# PIC32MK0512GPG048 register map
Vendor: Microchip
Registers are 32-bit, read-write, reset 0x0 unless marked. A register's access mark holds for its fields unless they carry their own. Addresses are absolute, and some are shared; only a register's first bit layout is shown; [hi:lo] are bit positions; {n}, {i} and the like mark numbered series.

## CLC4
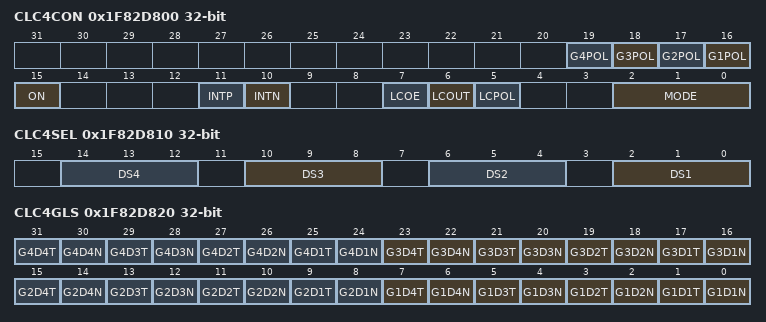
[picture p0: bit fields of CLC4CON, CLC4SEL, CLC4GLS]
0x1F82D800 CLC4CON
  [n+15] G{n}POL (n=1..4), [15] ON, [11] INTP, [10] INTN, [7] LCOE, [6] LCOUT, [5] LCPOL, [2:0] MODE
0x1F82D810 CLC4SEL
  [4n-2:4n-4] DS{n} (n=1..4)
0x1F82D820 CLC4GLS
  [8n-1] G{n}D4T (n=1..4), [8n-2] G{n}D4N (n=1..4), [8n-3] G{n}D3T (n=1..4), [8n-4] G{n}D3N (n=1..4), [8n-5] G{n}D2T (n=1..4), [8n-6] G{n}D2N (n=1..4), [8n-7] G{n}D1T (n=1..4), [8n-8] G{n}D1N (n=1..4)

## gpio_ports_upb
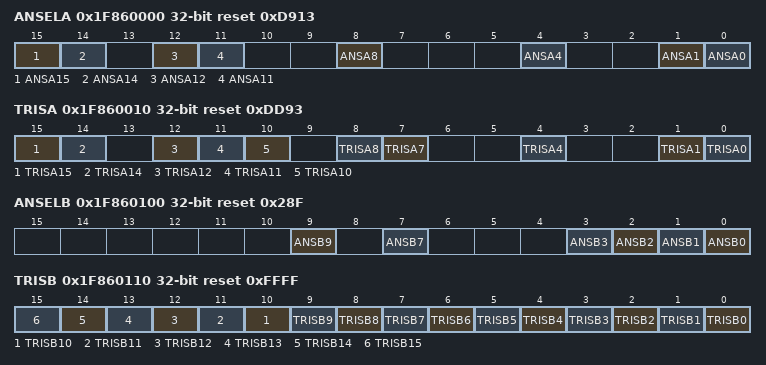
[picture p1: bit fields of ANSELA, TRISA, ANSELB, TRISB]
0x1F860000 ANSELA reset 0xD913
  [15] ANSA15, [14] ANSA14, [12] ANSA12, [11] ANSA11, [8] ANSA8, [4] ANSA4, [1] ANSA1, [0] ANSA0
0x1F860010 TRISA reset 0xDD93
  [15] TRISA15, [14] TRISA14, [12] TRISA12, [11] TRISA11, [10] TRISA10, [8] TRISA8, [7] TRISA7, [4] TRISA4, [1] TRISA1, [0] TRISA0
0x1F860100 ANSELB reset 0x28F
  [9] ANSB9, [7] ANSB7, [n] ANSB{n} (n=0..3)
0x1F860110 TRISB reset 0xFFFF
  [n] TRISB{n} (n=0..15)
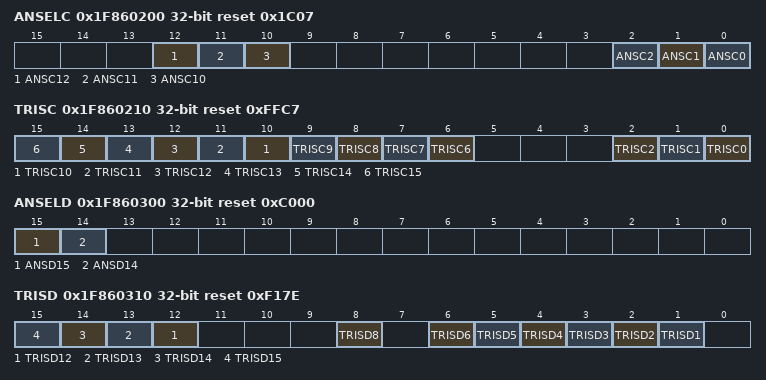
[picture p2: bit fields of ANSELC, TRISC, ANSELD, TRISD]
0x1F860200 ANSELC reset 0x1C07
  [12] ANSC12, [11] ANSC11, [10] ANSC10, [2] ANSC2, [1] ANSC1, [0] ANSC0
0x1F860210 TRISC reset 0xFFC7
  [n] TRISC{n} (n=6..15), [2] TRISC2, [1] TRISC1, [0] TRISC0
0x1F860300 ANSELD reset 0xC000
  [15] ANSD15, [14] ANSD14
0x1F860310 TRISD reset 0xF17E
  [n] TRISD{n} (n=12..15), [8] TRISD8, [n] TRISD{n} (n=1..6)

## PORTA
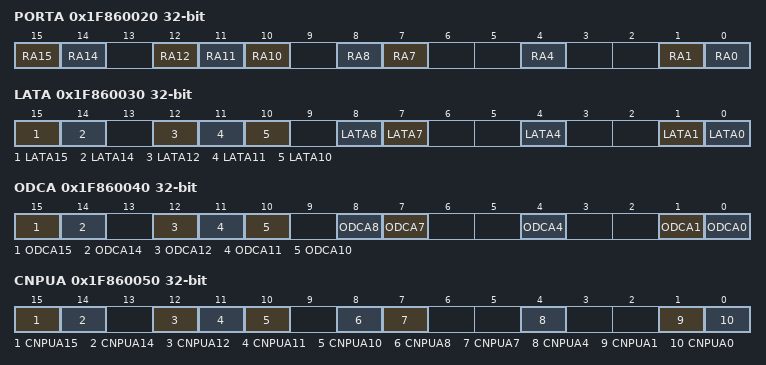
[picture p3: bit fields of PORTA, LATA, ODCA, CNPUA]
0x1F860020 PORTA reset not defined — (power-on value ----------------xx-xxx-xx--x--xx)
  [15] RA15, [14] RA14, [12] RA12, [11] RA11, [10] RA10, [8] RA8, [7] RA7, [4] RA4, [1] RA1, [0] RA0
0x1F860030 LATA reset not defined — (power-on value ----------------xx-xxx-xx--x--xx)
  [15] LATA15, [14] LATA14, [12] LATA12, [11] LATA11, [10] LATA10, [8] LATA8, [7] LATA7, [4] LATA4, [1] LATA1, [0] LATA0
0x1F860040 ODCA
  [15] ODCA15, [14] ODCA14, [12] ODCA12, [11] ODCA11, [10] ODCA10, [8] ODCA8, [7] ODCA7, [4] ODCA4, [1] ODCA1, [0] ODCA0
0x1F860050 CNPUA
  [15] CNPUA15, [14] CNPUA14, [12] CNPUA12, [11] CNPUA11, [10] CNPUA10, [8] CNPUA8, [7] CNPUA7, [4] CNPUA4, [1] CNPUA1, [0] CNPUA0
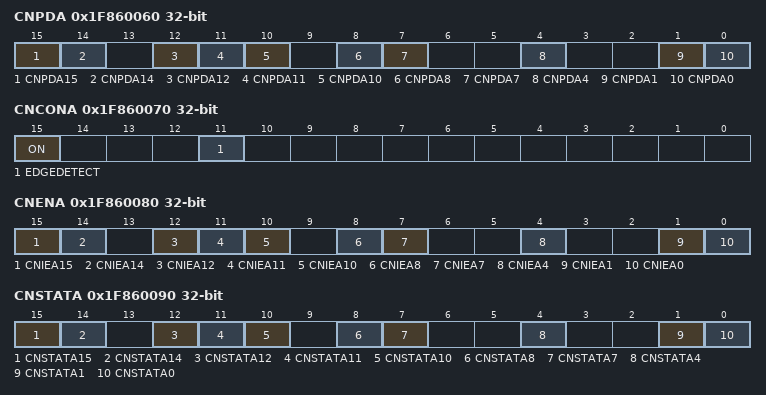
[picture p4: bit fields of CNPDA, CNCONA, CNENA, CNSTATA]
0x1F860060 CNPDA
  [15] CNPDA15, [14] CNPDA14, [12] CNPDA12, [11] CNPDA11, [10] CNPDA10, [8] CNPDA8, [7] CNPDA7, [4] CNPDA4, [1] CNPDA1, [0] CNPDA0
0x1F860070 CNCONA
  [15] ON, [11] EDGEDETECT
0x1F860080 CNENA
  [15] CNIEA15, [14] CNIEA14, [12] CNIEA12, [11] CNIEA11, [10] CNIEA10, [8] CNIEA8, [7] CNIEA7, [4] CNIEA4, [1] CNIEA1, [0] CNIEA0
0x1F860090 CNSTATA
  [15] CNSTATA15, [14] CNSTATA14, [12] CNSTATA12, [11] CNSTATA11, [10] CNSTATA10, [8] CNSTATA8, [7] CNSTATA7, [4] CNSTATA4, [1] CNSTATA1, [0] CNSTATA0
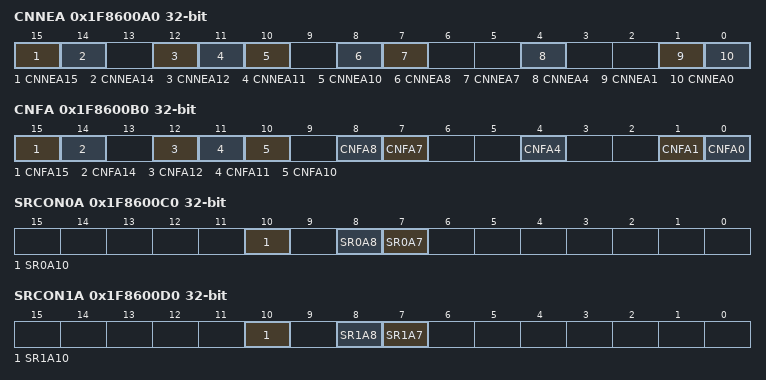
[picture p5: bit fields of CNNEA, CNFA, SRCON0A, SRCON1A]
0x1F8600A0 CNNEA
  [15] CNNEA15, [14] CNNEA14, [12] CNNEA12, [11] CNNEA11, [10] CNNEA10, [8] CNNEA8, [7] CNNEA7, [4] CNNEA4, [1] CNNEA1, [0] CNNEA0
0x1F8600B0 CNFA
  [15] CNFA15, [14] CNFA14, [12] CNFA12, [11] CNFA11, [10] CNFA10, [8] CNFA8, [7] CNFA7, [4] CNFA4, [1] CNFA1, [0] CNFA0
0x1F8600C0 SRCON0A
  [10] SR0A10, [8] SR0A8, [7] SR0A7
0x1F8600D0 SRCON1A
  [10] SR1A10, [8] SR1A8, [7] SR1A7

## PORTB
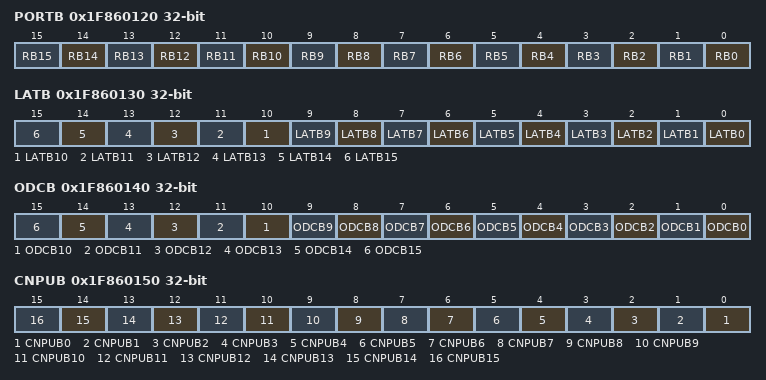
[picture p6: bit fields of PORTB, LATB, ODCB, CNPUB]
0x1F860120 PORTB reset not defined — (power-on value ----------------xxxxxxxxxxxxxxxx)
  [n] RB{n} (n=0..15)
0x1F860130 LATB reset not defined — (power-on value ----------------xxxxxxxxxxxxxxxx)
  [n] LATB{n} (n=0..15)
0x1F860140 ODCB
  [n] ODCB{n} (n=0..15)
0x1F860150 CNPUB
  [n] CNPUB{n} (n=0..15)
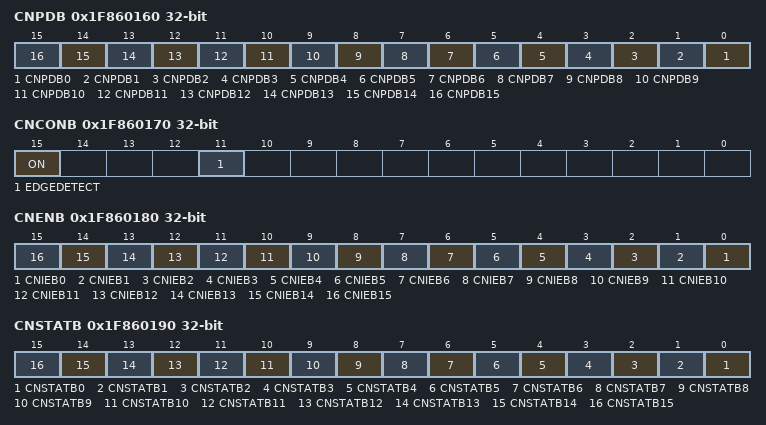
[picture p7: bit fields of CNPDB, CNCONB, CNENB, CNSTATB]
0x1F860160 CNPDB
  [n] CNPDB{n} (n=0..15)
0x1F860170 CNCONB
  [15] ON, [11] EDGEDETECT
0x1F860180 CNENB
  [n] CNIEB{n} (n=0..15)
0x1F860190 CNSTATB
  [n] CNSTATB{n} (n=0..15)
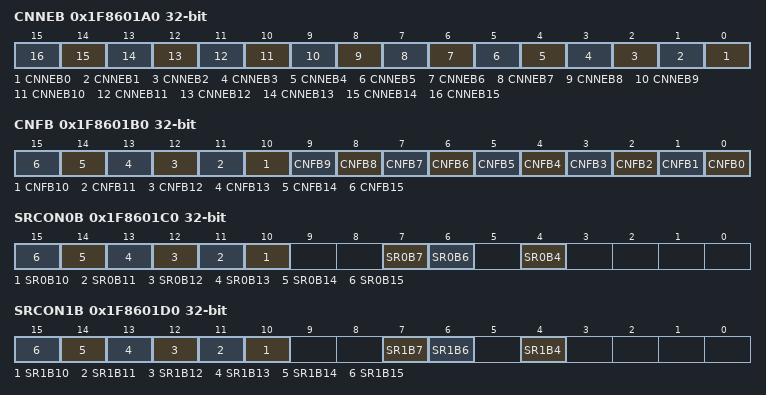
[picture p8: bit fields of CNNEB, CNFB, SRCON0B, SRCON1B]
0x1F8601A0 CNNEB
  [n] CNNEB{n} (n=0..15)
0x1F8601B0 CNFB
  [n] CNFB{n} (n=0..15)
0x1F8601C0 SRCON0B
  [n] SR0B{n} (n=10..15), [7] SR0B7, [6] SR0B6, [4] SR0B4
0x1F8601D0 SRCON1B
  [n] SR1B{n} (n=10..15), [7] SR1B7, [6] SR1B6, [4] SR1B4

## PORTC
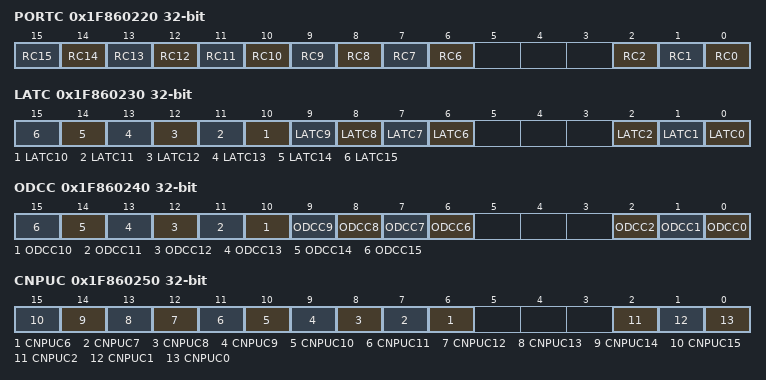
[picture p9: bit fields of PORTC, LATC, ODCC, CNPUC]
0x1F860220 PORTC reset not defined — (power-on value ----------------xxxxxxxxxx---xxx)
  [n] RC{n} (n=6..15), [2] RC2, [1] RC1, [0] RC0
0x1F860230 LATC reset not defined — (power-on value ----------------xxxxxxxxxx---xxx)
  [n] LATC{n} (n=6..15), [2] LATC2, [1] LATC1, [0] LATC0
0x1F860240 ODCC
  [n] ODCC{n} (n=6..15), [2] ODCC2, [1] ODCC1, [0] ODCC0
0x1F860250 CNPUC
  [n] CNPUC{n} (n=6..15), [2] CNPUC2, [1] CNPUC1, [0] CNPUC0
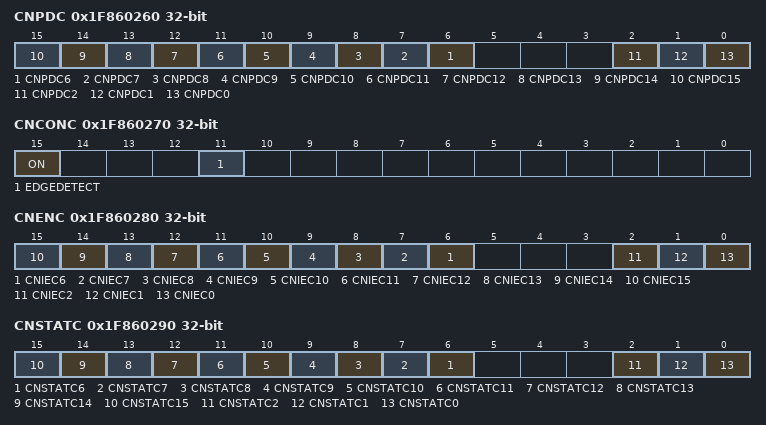
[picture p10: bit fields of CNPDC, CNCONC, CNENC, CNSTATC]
0x1F860260 CNPDC
  [n] CNPDC{n} (n=6..15), [2] CNPDC2, [1] CNPDC1, [0] CNPDC0
0x1F860270 CNCONC
  [15] ON, [11] EDGEDETECT
0x1F860280 CNENC
  [n] CNIEC{n} (n=6..15), [2] CNIEC2, [1] CNIEC1, [0] CNIEC0
0x1F860290 CNSTATC
  [n] CNSTATC{n} (n=6..15), [2] CNSTATC2, [1] CNSTATC1, [0] CNSTATC0
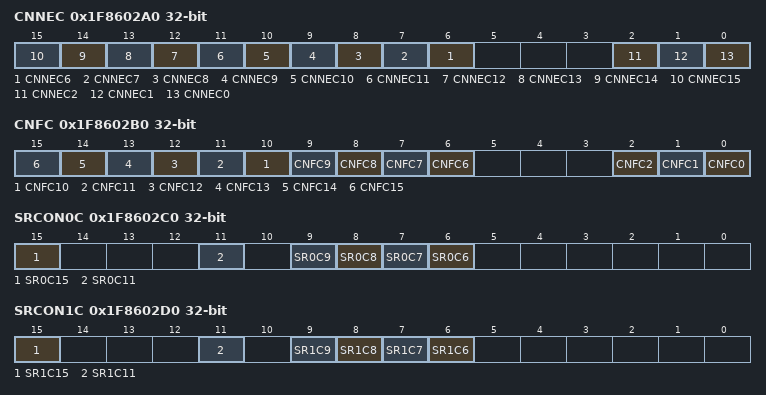
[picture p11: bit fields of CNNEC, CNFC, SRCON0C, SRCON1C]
0x1F8602A0 CNNEC
  [n] CNNEC{n} (n=6..15), [2] CNNEC2, [1] CNNEC1, [0] CNNEC0
0x1F8602B0 CNFC
  [n] CNFC{n} (n=6..15), [2] CNFC2, [1] CNFC1, [0] CNFC0
0x1F8602C0 SRCON0C
  [15] SR0C15, [11] SR0C11, [n] SR0C{n} (n=6..9)
0x1F8602D0 SRCON1C
  [15] SR1C15, [11] SR1C11, [n] SR1C{n} (n=6..9)
